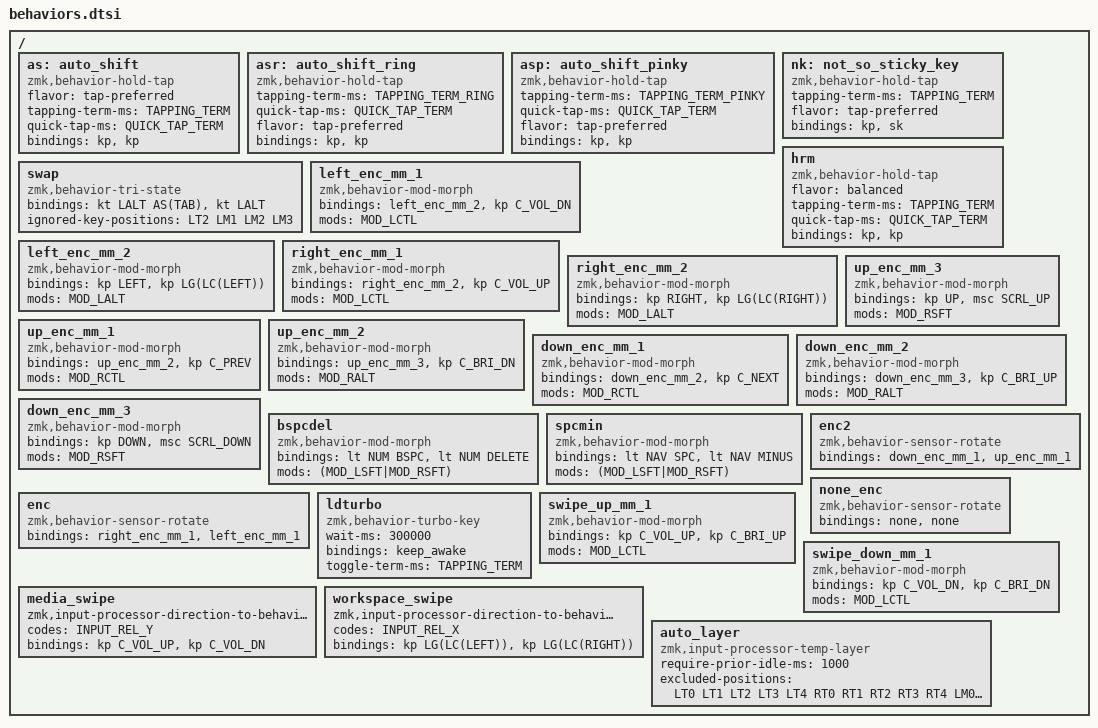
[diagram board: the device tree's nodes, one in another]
#define SK(KEY) &nk KEY KEY

#define RMODS (MOD_RGUI|MOD_RSFT|MOD_RALT|MOD_RCTL)
#define LMODS (MOD_LGUI|MOD_LSFT|MOD_LALT|MOD_LCTL)
#define ALLMODS (MOD_LGUI|MOD_LSFT|MOD_LALT|MOD_LCTL|MOD_RGUI|MOD_RSFT|MOD_RALT|MOD_RCTL)

/ {
    as: auto_shift {
        compatible = "zmk,behavior-hold-tap";
        #binding-cells = <2>;
        flavor = "tap-preferred";
        tapping-term-ms = <TAPPING_TERM>;
        quick-tap-ms = <QUICK_TAP_TERM>;
        bindings = <&kp &kp>;
    };

    asr: auto_shift_ring {
        compatible = "zmk,behavior-hold-tap";
        #binding-cells = <2>;
        tapping-term-ms = <TAPPING_TERM_RING>;
        quick-tap-ms = <QUICK_TAP_TERM>;
        flavor = "tap-preferred";
        bindings = <&kp &kp>;
    };

    asp: auto_shift_pinky {
        compatible = "zmk,behavior-hold-tap";
        #binding-cells = <2>;
        tapping-term-ms = <TAPPING_TERM_PINKY>;
        quick-tap-ms = <QUICK_TAP_TERM>;
        flavor = "tap-preferred";
        bindings = <&kp &kp>;
    };

    nk: not_so_sticky_key {
        compatible = "zmk,behavior-hold-tap";
        #binding-cells = <2>;
        tapping-term-ms = <TAPPING_TERM>;
        flavor = "tap-preferred";
        bindings = <&kp &sk>;
    };

    hrm: hrm {
        compatible = "zmk,behavior-hold-tap";
        #binding-cells = <2>;
        flavor = "balanced";
        tapping-term-ms = <TAPPING_TERM>;
        quick-tap-ms = <QUICK_TAP_TERM>;
        bindings = <&kp &kp>;
    };

    swap: swap {
        compatible = "zmk,behavior-tri-state";
        #binding-cells = <0>;
        bindings = <&kt LALT AS(TAB) &kt LALT>;
        ignored-key-positions = <LT2 LM1 LM2 LM3>;
    };

    left_enc_mm_1: left_enc_mm_1 {
        compatible = "zmk,behavior-mod-morph";
        #binding-cells = <0>;
        bindings = <&left_enc_mm_2 &kp C_VOL_DN>;
        mods = <MOD_LCTL>;
    };

    left_enc_mm_2: left_enc_mm_2 {
        compatible = "zmk,behavior-mod-morph";
        #binding-cells = <0>;
        bindings = <&kp LEFT &kp LG(LC(LEFT))>;
        mods = <MOD_LALT>;
    };

    right_enc_mm_1: right_enc_mm_1 {
        compatible = "zmk,behavior-mod-morph";
        #binding-cells = <0>;
        bindings = <&right_enc_mm_2 &kp C_VOL_UP>;
        mods = <MOD_LCTL>;
    };

    right_enc_mm_2: right_enc_mm_2 {
        compatible = "zmk,behavior-mod-morph";
        #binding-cells = <0>;
        bindings = <&kp RIGHT &kp LG(LC(RIGHT))>;
        mods = <MOD_LALT>;
    };

    up_enc_mm_1: up_enc_mm_1 {
        compatible = "zmk,behavior-mod-morph";
        #binding-cells = <0>;
        bindings = <&up_enc_mm_2 &kp C_PREV>;
        mods = <MOD_RCTL>;
    };

    up_enc_mm_2: up_enc_mm_2 {
        compatible = "zmk,behavior-mod-morph";
        #binding-cells = <0>;
        bindings = <&up_enc_mm_3 &kp C_BRI_DN>;
        mods = <MOD_RALT>;
    };

    up_enc_mm_3: up_enc_mm_3 {
        compatible = "zmk,behavior-mod-morph";
        #binding-cells = <0>;
        bindings = <&kp UP &msc SCRL_UP>;
        mods = <MOD_RSFT>;
    };

    down_enc_mm_1: down_enc_mm_1 {
        compatible = "zmk,behavior-mod-morph";
        #binding-cells = <0>;
        bindings = <&down_enc_mm_2 &kp C_NEXT>;
        mods = <MOD_RCTL>;
    };

    down_enc_mm_2: down_enc_mm_2 {
        compatible = "zmk,behavior-mod-morph";
        #binding-cells = <0>;
        bindings = <&down_enc_mm_3 &kp C_BRI_UP>;
        mods = <MOD_RALT>;
    };

    down_enc_mm_3: down_enc_mm_3 {
        compatible = "zmk,behavior-mod-morph";
        #binding-cells = <0>;
        bindings = <&kp DOWN &msc SCRL_DOWN>;
        mods = <MOD_RSFT>;
    };

    bspcdel: bspcdel {
        compatible = "zmk,behavior-mod-morph";
        #binding-cells = <0>;
        bindings = <&lt NUM BSPC &lt NUM DELETE>;
        mods = <(MOD_LSFT|MOD_RSFT)>;
    };

    spcmin: spcmin {
        compatible = "zmk,behavior-mod-morph";
        #binding-cells = <0>;
        bindings = <&lt NAV SPC &lt NAV MINUS>;
        mods = <(MOD_LSFT|MOD_RSFT)>;
    };

    enc: enc {
        compatible = "zmk,behavior-sensor-rotate";
        #sensor-binding-cells = <0>;
        bindings = <&right_enc_mm_1>, <&left_enc_mm_1>;
    };

    enc2: enc2 {
        compatible = "zmk,behavior-sensor-rotate";
        #sensor-binding-cells = <0>;
        bindings = <&down_enc_mm_1>, <&up_enc_mm_1>;
    };

    none_enc: none_enc {
        compatible = "zmk,behavior-sensor-rotate";
        #sensor-binding-cells = <0>;
        bindings = <&none>, <&none>;
    };

    ldturbo: ldturbo {
        compatible = "zmk,behavior-turbo-key";
        #binding-cells = <0>;
        wait-ms = <300000>;
        bindings = <&keep_awake>;
        toggle-term-ms = <TAPPING_TERM>;
    };

    swipe_up_mm_1: swipe_up_mm_1 {
        compatible = "zmk,behavior-mod-morph";
        #binding-cells = <0>;
        bindings = <&kp C_VOL_UP &kp C_BRI_UP>;
        mods = <MOD_LCTL>;
    };

    swipe_down_mm_1: swipe_down_mm_1 {
        compatible = "zmk,behavior-mod-morph";
        #binding-cells = <0>;
        bindings = <&kp C_VOL_DN &kp C_BRI_DN>;
        mods = <MOD_LCTL>;
    };

    media_swipe: media_swipe {
        compatible = "zmk,input-processor-direction-to-behaviors";
        #input-processor-cells = <0>;
        codes = <INPUT_REL_Y>;
        bindings = <&kp C_VOL_UP &kp C_VOL_DN>;
    };

    workspace_swipe: workspace_swipe {
        compatible = "zmk,input-processor-direction-to-behaviors";
        #input-processor-cells = <0>;
        codes = <INPUT_REL_X>;
        bindings = <&kp LG(LC(LEFT)) &kp LG(LC(RIGHT))>;
    };

    auto_layer: auto_layer {
        compatible = "zmk,input-processor-temp-layer";
        #input-processor-cells = <2>;
        require-prior-idle-ms = <1000>;
        excluded-positions = <LT0 LT1 LT2 LT3 LT4 RT0 RT1 RT2 RT3 RT4 LM0 LM1 LM2 LM3 LM4 RM0 RM1 RM2 RM3 RM4 LB0 LB1 LB2 LB3 LB4 RB0 RB1 RB2 RB3 RB4 LH0 LH1 LH2 RH0 RH1 RH2>;
    };
};
